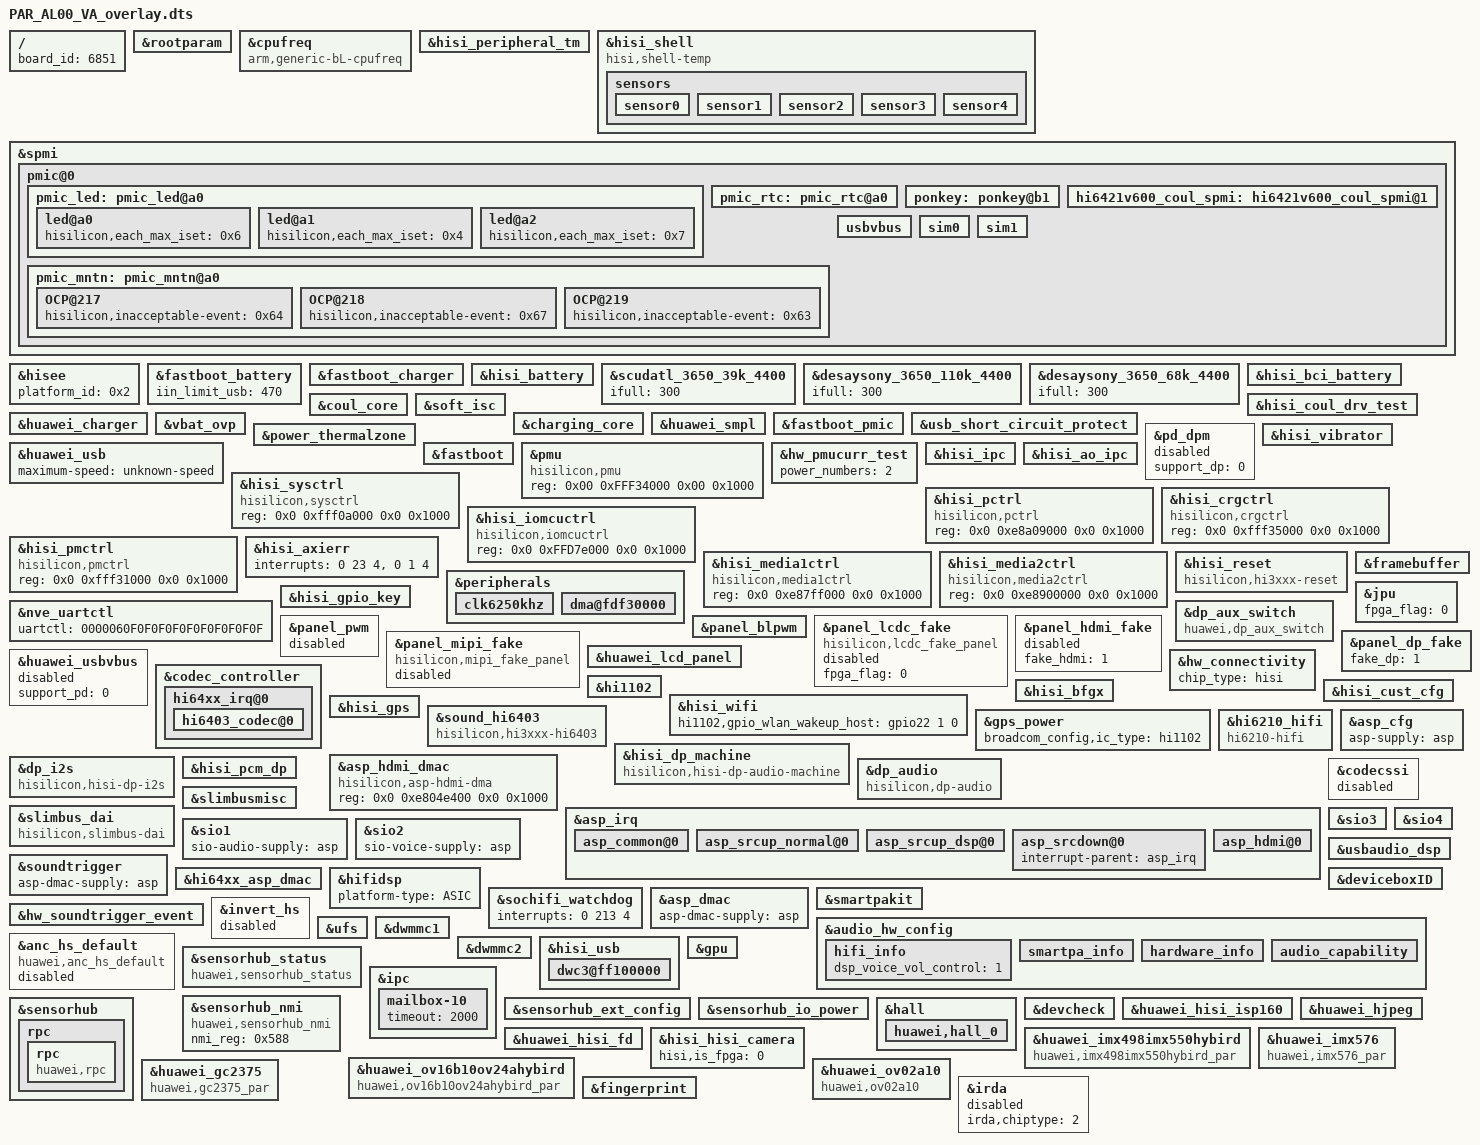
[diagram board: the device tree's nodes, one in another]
/**
 * Copyright (C) 2014 Hisilicon Ltd.
 *
 *  This program is free software; you can redistribute it and/or modify
 *  it under the terms of the GNU General Public License version 2 as
 *  publishhed by the Free Software Foundation.
 */

/dts-v1/;
/plugin/;

/include/ "PAR_AL00_VA_overlay_module_amba.dts"
/include/ "PAR_AL00_VA_overlay_module_sensorhub.dts"
/include/ "PAR_AL00_VA_overlay_module_ts_kit.dts"

/ {
	board_id = <6851>;
};

&rootparam {
        hisi,dtbo_idx = <66>;
    hisi,boardid = <6 8 5 1>;
    hisi,boardname = "PAR_AL00_VA";
};

	/* cpufreq  device */
	&cpufreq {
		compatible = "arm,generic-bL-cpufreq";
		status = "ok";
	};

	&hisi_peripheral_tm {
		hisi,peripheral_sensors = <8>;

		hisi,detect_system_h_tm_chanel = <7>;
		hisi,detect_system_h_tm_ntc = "austin_hkadc_soc_temp_table";
		hisi,detect_system_h_tm_state = "enable";
		hisi,detect_system_h_throttling = <53>;
		hisi,detect_system_h_shutdown = <55>;
		hisi,detect_system_h_below_vr_min = <53>;
		hisi,detect_system_h_over_skin = <12>;

		hisi,detect_flash_led_tm_chanel = <3>;
		hisi,detect_flash_led_tm_ntc = "austin_hkadc_soc_temp_table";
		hisi,detect_flash_led_tm_state = "disable";

		hisi,detect_charger_tm_chanel = <5>;
		hisi,detect_charger_tm_ntc = "austin_hkadc_soc_temp_table";
		hisi,detect_charger_tm_state = "enable";

		hisi,detect_pa_0_tm_chanel = <4>;
		hisi,detect_pa_0_tm_ntc = "austin_hkadc_pa_temp_table";
		hisi,detect_pa_0_tm_state = "enable";

		hisi,detect_pa_1_tm_chanel = <9>;
		hisi,detect_pa_1_tm_ntc = "austin_hkadc_pa_temp_table";
		hisi,detect_pa_1_tm_state = "disable";

		hisi,detect_dcxo0_tm_chanel = <15>;
		hisi,detect_dcxo0_tm_ntc = "austin_hkadc_adc_temp_table";
		hisi,detect_dcxo0_tm_state = "enable";

		hisi,detect_shell_tm_chanel = <7>;
		hisi,detect_shell_tm_ntc = "austin_hkadc_soc_temp_table";
		hisi,detect_shell_tm_state = "disable";

		hisi,detect_charger1_tm_chanel = <4>;
		hisi,detect_charger1_tm_ntc = "austin_hkadc_soc_temp_table";
		hisi,detect_charger1_tm_state = "disable";

		status = "ok";
	};

	&hisi_shell {
		compatible = "hisi,shell-temp";
		interval = <5000>;
		bias = <50000>;
		count = <6>;
		status = "ok";
		sensors {
			sensor0 {
				type = "system_h";
				coef = "-336","-311","1051","1148","761","-444";
			};
			sensor1 {
				type = "charger";
				coef = "2130","1143","-437","-800","478","2557";
			};
			sensor2 {
				type = "pa_0";
				coef = "16772","10594","5161","3140","7723","13923";
			};
			sensor3 {
				type = "dcxo0";
				coef = "-381","-1701","717","-1587","-2","-5589";
			};
			sensor4 {
				type = "Battery";
				coef = "12006","6346","3450","3824","4718","8474";
			};
		};
	};

	&spmi {
		pmic@0 {
			gpios = <&gpio28 0 0>;
			hisilicon,pmic_fpga_flag=<0>;
			pmic_led: pmic_led@a0 {
				status = "ok";
				led@a0 {
					hisilicon,each_max_iset = <0x6>;
				};
				led@a1 {
					hisilicon,each_max_iset = <0x4>;
				};
				led@a2 {
					hisilicon,each_max_iset = <0x7>;
				};
			};
			pmic_rtc: pmic_rtc@a0 {
				status = "ok";
			};
			ponkey:ponkey@b1{
				status = "ok";
			};
			pmic_mntn: pmic_mntn@a0 {
				status = "ok";
				OCP@217 {
					hisilicon,inacceptable-event = <0x64>;  //base E7
				};
				OCP@218 {
					hisilicon,inacceptable-event = <0x67>;  //base FF
				};
				OCP@219 {
					hisilicon,inacceptable-event = <0x63>;  //base 7F
				};
			};
			hi6421v600_coul_spmi: hi6421v600_coul_spmi@1 {
				status = "ok";
			};
			usbvbus {
				status = "ok";
			};
		};
	};

	&hisee {
		platform_id = <0x2>;
	};

	&fastboot_battery {
		iin_limit_usb = <470>;
		status = "ok";
	};
	&fastboot_charger {
		hw_charger_type = <4>;
		chip_i2c_num = <6>;
		status = "ok";
	};
	&hisi_battery {
		status = "ok";
		batt_name = <&scudatl_3650_39k_4400 &desaysony_3650_110k_4400 &desaysony_3650_68k_4400>;
	};

	&scudatl_3650_39k_4400 {
		ifull = <300>;
	};
	&desaysony_3650_110k_4400 {
		ifull = <300>;
	};
	&desaysony_3650_68k_4400 {
		ifull = <300>;
	};

	&hisi_bci_battery{
		battery_design_fcc = <3750>;
		battery_board_type = <2>; /*0:sft 1:udp 2:asic*/
		status = "ok";
	};
	&coul_core {
		adc_batt_id = <11>;
		adc_batt_temp = <10>;
		r_pcb = <0>;
		r_coul_mohm = <10>;
		startup_delta_soc = <10>;
		last_soc_enable = <1>;
		soc_at_term = <98>;
		iscd_enable = <1>;
		current_full_enable = <0>;
		ntc_compensation_is = <0>;
		ntc_temp_compensation_para =
			"0", "0";
		basp_policy = <
			4 100000 70  100 100 100 1 920001032 0
			3 70000  80  50  50  100 1 920001031 1
			2 40000  88  40  50  100 1 920001029 1
			1 20000  100 20  0   100 1 920001037 0
			0 0      0   0   0   100 0 0         0
		>;
		basp_ver = <2>;
		batt_backup_nv_flag = <1>;
		normal_cutoff_vol_mv = <3000>;
		low_vol_filter_cnt = <6>;
		status = "ok";
	};
	&soft_isc {
		/* 0 means invalid; 1 is successive judgement; others is illegal */
		fatal_isc_trigger_type = <1>;
		/*DMD normal-charge-limitation direct-charge-limitation Uevent OCV-update*/
		fatal_isc_actions = <1 1 1 1 1>;
		fatal_isc_trigger_condition = <50000 3 920001078 100000 2 920001077>;
	};
	&hisi_coul_drv_test{
		status = "ok";
	};
	&huawei_charger {
		pd_support = <0x0>;
		fcp_vindpm = <8100>;
		charge_done_sleep_enabled;
		leak_current_check = <1>;
		status = "ok";
	};
	&vbat_ovp{
		status = "ok";
	};
	&charging_core{
		status = "ok";
		iterm = <150>;
		iin_ac = <2000>;
		ichg_ac = <2100>;
		iin_usb = <470>;
		ichg_usb = <500>;
		ichg_fcp = <3600>;
		iin_fcp = <2000>;
		vdpm_buf_limit = <300>;
		iin_weaksource = <470>;
		vdpm_para =
			"-32767", "4080", "4460", "280",
			"4080", "32767", "4675", "280";
		inductance_para =
			"-32767", "15", "2000", "0",
			"15", "32767", "2000", "0";
	};
	&huawei_smpl{
		status = "ok";
	};
               &fastboot_pmic{
                             hisilicon,init-reg-num = <1>;
                             hisilicon,init-reg-addrs = <0x243>;
                             hisilicon,init-reg-vals  = <0x06>;
               };
	&usb_short_circuit_protect{
		open_mosfet_temp = <20>;
		close_mosfet_temp = <10>;
		interval_switch_temp = <15>;
		status = "ok";
	};

	&power_thermalzone {
		status = "ok";
	};

	&pd_dpm {
		status = "disabled";
		support_dp = <0>;
	};
	&huawei_usb {
		maximum-speed = "unknown-speed";
		status = "ok";
	};
	&hisi_vibrator {
		status = "ok";
		vibrator_vout_min_voltage = <3000000>;
                vibrator_vout_max_voltage = <3000000>;
	};
	&fastboot {
		i2c3-pin = <0>;
		gpio-keyup = <231>;
		gpio-keydown = <230>;
		uart-board-type = <1>;
		/*UDP_TYPE 0,PRODUCT 1,FPGA 2,EMU 3*/
		lpm3-board-type = <2>;
		jtagtosd-board-type = <1>;
		motor-vib_type = <0>;
		/*is_fpga = <0x55AA5AA5>;*/

		i2c-select = <1>;
		i2c-sel0-gpio = <44>;
		i2c-sel1-gpio = <45>;
		i2c-sel0-val = <0>;
		i2c-sel1-val = <0>;
	};

	&pmu{
		compatible = "hisilicon,pmu";
		reg = <0x00 0xFFF34000 0x00 0x1000>;
		status = "ok";
	};

	&hw_pmucurr_test{
		power_numbers = <2>;
		status = "ok";
	};

	&hisi_ipc {
		status = "ok";
	};
	&hisi_ao_ipc {
		status = "ok";
	};

        &hisi_sysctrl {
                compatible = "hisilicon,sysctrl";
                reg = <0x0 0xfff0a000 0x0 0x1000>;
                status = "ok";
        };

        &hisi_pctrl {
                compatible = "hisilicon,pctrl";
                reg = <0x0 0xe8a09000 0x0 0x1000>;
                status = "ok";
        };

        &hisi_crgctrl {
                compatible = "hisilicon,crgctrl";
                reg = <0x0 0xfff35000 0x0 0x1000>;
                status = "ok";
        };

        &hisi_iomcuctrl {
                compatible = "hisilicon,iomcuctrl";
                reg = <0x0 0xFFD7e000 0x0 0x1000>;
                status = "ok";
		};
        &hisi_pmctrl {
                compatible = "hisilicon,pmctrl";
                reg = <0x0 0xfff31000 0x0 0x1000>;
                status = "ok";
        };
        &hisi_media1ctrl {
                compatible = "hisilicon,media1ctrl";
                reg = <0x0 0xe87ff000 0x0 0x1000>;
                status = "ok";
        };
        &hisi_media2ctrl {
                compatible = "hisilicon,media2ctrl";
                reg = <0x0 0xe8900000 0x0 0x1000>;
                status = "ok";
        };

	&hisi_axierr {
	        interrupts = <0 23 4>, <0 1 4>;
	        status = "ok";
        };

    &hisi_reset {
            compatible = "hisilicon,hi3xxx-reset";
            status = "ok";
        };

	&peripherals {

		clk6250khz {
			#clock-cells = <0>;
			clock-frequency = <6297600>;
			clock-output-names = "clk6250khz";
		};
/*
		clk4800khz {
			compatible = "fixed-clock";
			#clock-cells = <0>;
			clock-frequency = <32768>;
			clock-output-names = "clk4800khz";
		};
*/

		dma@fdf30000 {
			status = "ok";
		};

	};
	&nve_uartctl {
		uartctl = "0000060F0F0F0F0F0F0F0F0F0F";
	};

	&hisi_gpio_key {
		pinctrl-names = "default", "idle";
		pinctrl-0 = <&gpio231_cfg_func &gpio230_cfg_func>;
		pinctrl-1 = <&gpio231_cfg_idle &gpio230_cfg_idle>;
		gpio-keyup,gpio-irq = <&gpio28 7 0>;
		gpio-keydown,gpio-irq = <&gpio28 6 0>;
		status = "ok";
	};

	&dp_aux_switch {
	        compatible = "huawei,dp_aux_switch";
	        pinctrl-names = "default", "idle";
	        pinctrl-0 = <&gpio009_pmx_func &gpio010_pmx_func &gpio009_cfg_func &gpio010_cfg_func>;
	        pinctrl-1 = <&gpio009_pmx_idle &gpio010_pmx_idle &gpio009_cfg_idle &gpio010_cfg_idle>;
	        cs-gpios = <&gpio1 1 0>, <&gpio1 2 0>;
	        status = "ok";
	};

	/* display start */
	&framebuffer{
		fpga_flag = <0>;
		//FB_ACCEL_KIRIN970_ES  0x20;FB_ACCEL_KIRIN970  0x40;
		dss_version_tag = <0x40>;
	};

	/*jpeg decode */
	&jpu {
		fpga_flag = <0>;
	};

	&panel_pwm {
		#address-cells = <2>;
		#size-cells = <2>;
		clocks = <&clk_gate_pwm>;
		clock-names = "clk_pwm";
		//pinctrl-names = "default","idle";
		//pinctrl-0 = <&gpio182_pmx_func &gpio182_cfg_func>;
		//pinctrl-1 = <&gpio182_pmx_idle &gpio182_cfg_idle>;
		fpga_flag = <0>;
		status = "disabled";
	};

	&panel_blpwm {
		#address-cells = <2>;
		#size-cells = <2>;
		clocks = <&clk_gate_blpwm>;
		clock-names = "clk_blpwm";
		pinctrl-names = "default","idle";
		pinctrl-0 = <&gpio184_pmx_func &gpio185_pmx_func &gpio184_cfg_func &gpio185_cfg_func>;
		pinctrl-1 = <&gpio184_pmx_idle &gpio185_pmx_idle &gpio184_cfg_idle &gpio185_cfg_idle>;
		fpga_flag = <0>;
		status = "ok";
	};

	&panel_lcdc_fake {
		#address-cells = <2>;
		#size-cells = <2>;
		compatible = "hisilicon,lcdc_fake_panel";
		fpga_flag = <0>;
		status = "disabled";
	};

	&panel_mipi_fake {
		#address-cells = <2>;
		#size-cells = <2>;
		compatible = "hisilicon,mipi_fake_panel";
		gpios = <&gpio4 2 0>, <&gpio6 3 0>, <&gpio1 4 0>; /* vsn, bl_enable, vsp*/
		gpio_nums = <34 51 12>;
		fpga_flag = <0>;
		lcd-bl-ic-name = "LM36923YFFR";
		bl_enable_flag = <0>;
		status = "disabled";
	};

	&huawei_lcd_panel {
		lcd_ldo_name = "LDO4";
		lcd_ldo_channel = <2>;
		lcd_ldo_threshold = <200>;
		lcd-bl-ic-name = "blpwm_blic";
	};


	&panel_hdmi_fake {
		fake_hdmi = <1>;
		status = "disable";
	};
	&panel_dp_fake {
		fake_dp = <1>;
		status = "ok";
	};
	&huawei_usbvbus {
		support_pd = <0>;
		status = "disabled";
	};

	/* display end */



	/* audio device beg */
	&codec_controller {
		gpios = <&gpio18 4 0>; /* GPIO_148 */
		gpio_reset = <31>; /* GPIO_031*/
		gpio_codec_ssi = <203>;
		gpio_codec_ssi_func = <1>;
		pm_runtime_support;
		status = "ok";

		hi64xx_irq@0 {
			status = "ok";

			hi6403_codec@0{
				hisilicon,mic_num = <2>;
				hisilicon,hs_4_pole_min_voltage = <900>;
				use_stereo_smartpa = <0>;
				hisilicon,hs_det_trigger = <1>;
				hisilicon,hs_extern_cable_min_voltage = <2651>;
				hisilicon,hs_extern_cable_max_voltage = <2700>;
				hs_detect_extern_cable = <1>;
				hisilicon,wakeup_hisi_algo_support = <1>;
				status = "ok";
			};
		};
	};

	&hw_connectivity {
		chip_type = "hisi";
	};

	/*power*/
	&hi1102 {
	};

	/*wifi*/
	&hisi_wifi {
		hi1102,gpio_wlan_wakeup_host =  <&gpio22 1 0>;
	};

	/*bfgx*/
	&hisi_bfgx {
		hi1102,gpio_bfgn_wakeup_host = <&gpio27 2 0>;
		hi1102,uart_port = "/dev/ttyAMA4";
	hi1102,uart_pclk_normal;
	/**ir begin*/
		hi1102,irled_power_type=<0x00>;
		have_ir;
	/**ir end*/
	};

	/*hisi connectivity customize*/
	&hisi_cust_cfg {
	};

	/*hisi gps*/
	&hisi_gps {
		clocks = <&clk_gate_gps_ref>, <&clk_mux_gps_ref>, <&clk_gate_mdm2gps0>, <&clk_gate_mdm2gps1>, <&clk_gate_mdm2gps2>;
		clock-names = "ref_clk", "mux_clk", "mdm_clk0", "mdm_clk1", "mdm_clk2";
		/*hisi gps iomux config*/
		pinctrl-names = "default", "idle";
		pinctrl-0 = <&gpio005_pmx_func &gpio005_cfg_func>;
		pinctrl-1 = <&gpio005_pmx_idle &gpio005_cfg_idle>;
	};

	&gps_power{
		broadcom_config,ic_type="hi1102";
	};
	&sound_hi6403 {
		compatible = "hisilicon,hi3xxx-hi6403";
		status = "ok";
	};

	&hi6210_hifi {
		compatible = "hi6210-hifi";
		status = "ok";
	};

	&hisi_dp_machine {
		compatible = "hisilicon,hisi-dp-audio-machine";
		status = "ok";
	};

	&asp_hdmi_dmac {
		compatible = "hisilicon,asp-hdmi-dma";
		reg = <0x0 0xe804e400 0x0 0x1000>;
		status = "ok";
	};

	&asp_cfg {
		asp-supply = <&asp>;
		status = "ok";
	};

	&dp_i2s {
		compatible = "hisilicon,hisi-dp-i2s";
		status = "ok";
        };

	&dp_audio {
		compatible = "hisilicon,dp-audio";
		status = "ok";
        };

	&hisi_pcm_dp {
		interrupts = <0x0 0x96 0x4>;
		interrupt-names = "asp_hdmi_dma";
		dp-pcm-supply = <&asp>;
		status = "ok";
	};

	&asp_irq{

		asp_common@0 {
		};

		asp_srcup_normal@0 {
			asp-srcup-normal-supply = <&asp>;
			interrupt-parent = <&asp_irq>;
			interrupts = <0x1 0x0>;
			interrupt-names = "asp_srcup_normal";
		};

		asp_srcup_dsp@0 {
		};

		asp_srcdown@0 {
			interrupt-parent = <&asp_irq>;
		};

		asp_hdmi@0 {
			interrupt-parent = <&asp_irq>;
			interrupts = <0x0 0x0>;
			interrupt-names = "asp_irq_hdmi";
		};
	};
	&codecssi {
		/* ssi pinctrl */
		pinctrl-names = "default", "idle";
		pinctrl-0 = <&gpio203_cfg_func &gpio203_pmx_func>;
		pinctrl-1 = <&gpio203_cfg_idle &gpio203_pmx_idle>;
		status = "disabled";
	};
	&slimbusmisc {
		interrupts = <0x0 0x96 0x4>;
		interrupt-names = "asp_irq_slimbus";
		slimbus-reg-supply = <&asp>;
		pinctrl-names = "default", "idle";
		pinctrl-0 = <&gpio192_pmx_func
				&gpio193_pmx_func
				&gpio192_cfg_func
				&gpio193_cfg_func>;
		pinctrl-1 = <&gpio192_pmx_idle
				&gpio193_pmx_idle
				&gpio192_cfg_idle
				&gpio193_cfg_idle>;
		slimbus-ssi-sel = "slimbus";
		asp_power_state_offset = <0x06c>;
		slimbusclk_offset = <0x038>;
		slimbusdata_offset = <0x03c>;
		slimbusclk_cfg_offset = <0x864>;
		slimbusdata_cfg_offset = <0x868>;
		platform-type   = "ASIC";
		codec-type = "slimbus-6403cs";
		clk_asp_subsys = <415000>;
		slimbus_dynamic_freq= "true";
		pm_runtime_support;
		status = "ok";
	};
	&slimbus_dai {
		compatible = "hisilicon,slimbus-dai";
		status = "ok";
	};

	&sio1 {
		sio-audio-supply = <&asp>;
		/* wbd
		pinctrl-names = "default", "idle";
		pinctrl-0 = <&gpio183_pmx_func
				    &gpio184_pmx_func
				    &gpio185_pmx_func
				    &gpio186_pmx_func
				    &gpio183_cfg_func
				    &gpio184_cfg_func
				    &gpio185_cfg_func
				     &gpio186_cfg_func>;
		pinctrl-1 = <&gpio183_pmx_idle
				    &gpio184_pmx_idle
				    &gpio185_pmx_idle
				    &gpio186_pmx_idle
				    &gpio183_cfg_idle
				    &gpio184_cfg_idle
				    &gpio185_cfg_idle
				    &gpio186_cfg_idle>;
		*/
		status = "ok";
	};

	&sio2 {
		sio-voice-supply = <&asp>;
		/* wbd
		pinctrl-names = "default", "idle";
		pinctrl-0 = <&gpio043_pmx_func
				     &gpio044_pmx_func
				     &gpio045_pmx_func
				     &gpio046_pmx_func
				     &gpio043_cfg_func
				     &gpio044_cfg_func
				     &gpio045_cfg_func
				     &gpio046_cfg_func>;
			pinctrl-1 = <&gpio043_pmx_idle
				     &gpio044_pmx_idle
				     &gpio045_pmx_idle
				     &gpio046_pmx_idle
				     &gpio043_cfg_idle
				     &gpio044_cfg_idle
				     &gpio045_cfg_idle
				     &gpio046_cfg_idle>;
		*/
		status = "ok";
	};

	&sio3 {
	};

	&sio4 {
	};

	&soundtrigger {
		asp-dmac-supply = <&asp>;
		status = "ok";
	};

	&hi64xx_asp_dmac {
		asp-dmac-supply = <&asp>;
		interrupts = <0 216 4>;
		interrupt-names = "asp_dma_irq";
		status = "ok";
	};

	&hifidsp {
			platform-type = "ASIC";
	};

	&sochifi_watchdog {
		interrupts = <0 213 4>;
		status = "ok";
	};

	&asp_dmac {
		asp-dmac-supply = <&asp>;
		status = "ok";
	};

	&usbaudio_dsp {
	};

	&deviceboxID {
		check_mode = "gpio";
		box_num = <1>;
		enable_boxID = <1 0 0 0>;
		gpio_num = <1 0 0 0>;
		gpio_speakerID = <&gpio17 1 0>;
		speaker_map = <3 1>;/*3 means GD, 1 means AAC*/
		pinctrl-names = "default", "idle";
		pinctrl-0 = <&gpio137_pmx_func &gpio137_cfg_func>;
		pinctrl-1 = <&gpio137_pmx_idle &gpio137_cfg_idle>;
		deviceboxID_limit = <500>;
		status = "ok";
	};

	&smartpakit {
		/* 0 hisi, 1 qcom */
		soc_platform = <0>;
		/* algo running on: 0 codec_dsp, 1 soc_dsp, 2 smartpa_dsp, 3 simple pa(not smpartpa) */
		algo_in = <0>;
		/* algo_in params need match out_device for smartpa.
		 * Now, up to only support four pa, so out_device = <0 0 0 0>;
		 * 1. This array is arranged in the following order:
		 *    <0 1 2 3>
		 *    <pril prir secl secr>
		 * 2. This array element value is 0 or 1:
		 *    smartpa: 0 speaker, 1 receiver
		 *    simple pa: out_device not applicable, only set 0 to indicate pa_num
		 * 3. The length of this array is variable, for example:
		 *    single pa: out_device = <0>;
		 *    two pa: out_device = <0 0>;
		 *    four pa: out_device = <1 1 0 0>; */
		out_device = <0>;
		dsp_img_name = "hifi_6403_tas_devkit.img";
		status = "ok";
	};

	&audio_hw_config {
		product_name = "PAR";
		multi_mic_enable = "false";
		vqm_enable = "true";
		spk_pa_name = "smartpakit";
		cust_name = "audio_custom";
		soc_name = "hi363x";
		codec_name = "hi6403";
		codec_dsp_algo = "mad";
		modem_sio_master = "false";
		asr_enable = "true";
		analog_earpiece_enable = "false";
		status = "ok";
		audio_sar_support = "true";
		karaoke_mic_conf_support = "true";/*use specific mic path to enhance karaoke UE*/

		hifi_info {
			dsp_voice_vol_control = "1";/* 1 :need socdsp control volume; 0:platform codec */
		};

		smartpa_info {
			pa_num = "1";
			algo_in = "0"; /*algo running on: 0 codec_dsp | 1 soc_dsp | 2 smartpa_dsp */
			pa_type = "0001";/*0 as receiver pa 1 as spk pa eg:0011 means dual smartpa and only as spk, 0001 means dual smartpa and as spk+rcv*/
			status = "ok";
		};

		hardware_info {
			mic_num = "2";
			mic_type = "0003";/*0001 deputy mic   0002 main mic   0004 deputy mic2   0008 main mic2*/
			status = "ok";
		};

		audio_capability {
			bwe_ui_support = "false";
			bwe_support = "true";
			swb_support = "true";
			wnr_support = "false";
			nv_evs_support = "true";
			lvm_support = "false";
			dhf_support = "false";
			voice_anc_support = "false";
			dual_smartpa_support = "false";
			stereo_handfree_support = "false";
			spk_rcv_stereo_support = "false";
			earphone_multi_eq_support = "false";
			vdr_ui_support = "false";
			asr_vibrate_support = "true";
			mmi_capture_enable = "true";
			irda_support = "false";
			visualizer_support = "true";
			visualizer_frame = "Medium";
			/*
				sound trigger feature.
				false: this product doesn't support soundtrigger feature.
				2.0: this product supports the twice wakeup feature.
			*/
			soundtrigger_version = "2.0";
			/*
				max stream volume to replace Android default volume.
			*/
			max_stream_volume = "15";
			/*
				usb compatibility report feature.
				true: this product needs usb compatibility report.
				false: this product doesn't need usb compatibility report.
			*/
			usb_compatibility_report = "true";
			/*
				use hisilicon wakeup engine.
				true: use hisilicon wakeup engine.
				false: DO NOT use hisilicon wakeup engine.
			*/
			wakeup_hisiengine = "true";
		};
	};

	&hw_soundtrigger_event{
		status = "ok";
	};

	&invert_hs {
		gpios = <&gpio26 0 0>;
		gpio_type = <0>;
		pinctrl-names = "default", "idle";
		pinctrl-0 = <&gpio208_pmx_func &gpio208_cfg_func>;
		pinctrl-1 = <&gpio208_pmx_idle &gpio208_cfg_idle>;
		status = "disabled";
	};

	&anc_hs_default {
		compatible = "huawei,anc_hs_default";
		status = "disabled";
	};

	/* audio device end */

	/*bootdevice: bootdevice {
		boot-from-emmc;
	};*/

	/* UFS */
	&ufs {
		ufs-kirin-use-rate-B;
		ufs-kirin-broken-fastauto;
		/*ufs-kirin-use-one-line;*/
		ufs-kirin-use-HS-GEAR3;
		/*ufs-kirin-use-HS-GEAR2;*/
		/*ufs-kirin-use-HS-GEAR1;*/
		ufs-kirin-unipro-termination;
		/*ufs-kirin-unipro-scrambing;*/
		/*ufs-kirin-disable-pm-runtime;*/
		/*ufs-kirin-use-auto-H8*/
		ufs-kirin-broken-clk-gate-bypass;
		status = "ok";
	};

	/* eMMC 4.5 */

	/* SD */
	&dwmmc1 {
		vmmc-supply = <&ldo16>;
		vqmmc-supply = <&ldo9>;
		cd-vol = <1>;
		cd-gpio = <&gpio25 5 0>;
		shared-irq = <1>;
		cs_sd_timing_config;
		status = "ok";
	};

	/* wifi */
	&dwmmc2 {
	};

	&hisi_usb {
		usb_ldo_disable = <1>;
		usb_aclk_freq = <238000000>;
		usb_support_dp = <0>;

		eye_diagram_param = <0x37CE7E7>;
		eye_diagram_host_param = <0x33DE7E7>;
		usb_support_check_voltage = <0>;
		dwc3@ff100000 {
			quirk_dplus_gpio = <0>;
			maximum-speed = "high-speed";
		};
	};

	&gpu {
		status = "ok";
	};

	&sensorhub_status{
		compatible = "huawei,sensorhub_status";
		status= "ok";
	};

	&ipc {	/* add for fpga because iom7 start too slow锛?300ms锛?*/
		mailbox-10 {
			timeout = <2000>;
		};
	};

	&sensorhub_nmi{
		compatible = "huawei,sensorhub_nmi";
		nmi_reg=<0x588>;
	};

	&sensorhub_ext_config {
		akm_need_current = "no";
		invensense_exist = "no";
		isensor_version = "no";
		sensor_1v8_from_pmic = "no";
		adapt_sensor_list_id = <2 6 7 8 11 12 13 14 15 17 18 21 29>;
		adapt_file_id = <8 9 14 15>;
	};

	&sensorhub_io_power{
		sensor-io-supply = <&ldo24>;
		need-reset = <1>;
		set-3v = <1>;
		status="ok";
	};

	&sensorhub{
		rpc{
            		rpc{
			compatible = "huawei,rpc";
			file_id = <0x18>;
			sensor_list_info_id = <24>;
			sensor_type = "rpc";
			sensorlist_name = "rpc";
			mask = <0xFFFF 0x200 0x200 0xFFFF 0xFFFF 0xFFFF 0xFFFF 0xFFFF
				0xFFFF 0xFFFF 0xFFFF 0xFFFF 0xFFFF 0xFFFF 0xFFFF 0xFFFF
				0xFFFF 0xFFFF 0xFFFF 0xFFFF 0xFFFF 0xFFFF 0xFFFF 0xFFFF
				0xFFFF 0xFFFF 0xFFFF 0xFFFF 0xFFFF 0xFFFF 0xFFFF 0xFFFF>;
			table = <0xFFFF 0x200 0x0 0xFFFF 0xFFFF 0xFFFF 0xFFFF 0xFFFF
				 0xFFFF 0xFFFF 0xFFFF 0xFFFF 0xFFFF 0xFFFF 0xFFFF 0xFFFF
				 0xFFFF 0xFFFF 0xFFFF 0xFFFF 0xFFFF 0xFFFF 0xFFFF 0xFFFF
				 0xFFFF 0xFFFF 0xFFFF 0xFFFF 0xFFFF 0xFFFF 0xFFFF 0xFFFF>;
			default_value = <0x1D>;
			status = "ok";
            };
        };

	};

	&hall {
		huawei,hall_0{
			huawei,single-n-pole = <&gpio27 1 0>;
			huawei,type = <0x01>;
			huawei,default-state = "on";
		};
	};

	&devcheck {
		touch_panel = <2>;
		compass = <3>;
		g_sensor = <3>;
		gyroscope = <3>;
		nfc = <0>;
		dc_dc = <3>;
		tps = <0>;
		l_sensor = <2>;
		charge = <3>;
		antenna_ctl = <0>;
		airpress = <0>;
		laser = <0>;
		status = "ok";
	};

	&huawei_hisi_isp160 {
		hisi,is_fpga = <0>;
                pinctrl-names = "default", "idle";
                pinctrl-0 = <
                 &gpio017_pmx_func
                 &gpio018_pmx_func
                 &gpio019_pmx_func
                 &gpio020_pmx_func
                 &gpio021_pmx_func
                 &gpio022_pmx_func
                 &gpio023_pmx_func
                 &gpio024_pmx_func
                 &gpio025_pmx_func
                 &gpio008_pmx_func
                 &gpio004_pmx_func
                 &gpio136_pmx_func
                 &gpio013_pmx_func
                 &gpio032_pmx_func

                 &gpio017_cfg_func
                 &gpio018_cfg_func
                 &gpio019_cfg_func
                 &gpio020_cfg_func
                 &gpio021_cfg_func
                 &gpio022_cfg_func
                 &gpio023_cfg_func
                 &gpio024_cfg_func
                 &gpio025_cfg_func
                 &gpio008_cfg_func
                 &gpio004_cfg_func
                 &gpio136_cfg_func
                 &gpio013_cfg_func
                 &gpio032_cfg_func
                 >;
                pinctrl-1 = <
                 &gpio017_pmx_idle
                 &gpio018_pmx_idle
                 &gpio019_pmx_idle
                 &gpio020_pmx_idle
                 &gpio021_pmx_idle
                 &gpio022_pmx_idle
                 &gpio023_pmx_idle
                 &gpio024_pmx_idle
                 &gpio025_pmx_idle
                 &gpio008_pmx_idle
                 &gpio004_pmx_idle
                 &gpio136_pmx_idle
                 &gpio013_pmx_idle
                 &gpio032_pmx_idle

                 &gpio017_cfg_idle
                 &gpio018_cfg_idle
                 &gpio019_cfg_idle
                 &gpio020_cfg_idle
                 &gpio021_cfg_idle
                 &gpio022_cfg_idle
                 &gpio023_cfg_idle
                 &gpio024_cfg_idle
                 &gpio025_cfg_idle
                 &gpio008_cfg_idle
                 &gpio004_cfg_idle
                 &gpio136_cfg_idle
                 &gpio013_cfg_idle
                 &gpio032_cfg_idle
                 >;
                status = "ok";
	};

	&huawei_hjpeg {
		huawei,hjpeg-base = <0xE8300000 0x1000>;
		huawei,smmu-base = <0xE8320000 0x20000>;
		huawei,cvdr-base = <0xE8302000 0x1000>;
		huawei,subctrl-base = <0xE8304000 0x4>;
		huawei,chip_type = <1>;
		huawei,smmu_bypass = <0>;
		huawei,smmu_type = <1>;
		huawei,power_control = <0>;
		huawei,cvdr = <0 0 0>;
		huawei,stream_id = <0 4 5>;
		clocks = <&clk_gate_jpg_func>;
		clock-names = "clk_jpg_func";
		clock-value = <554000000>;
		clock-low-frequency = <277000000>;
		power-off-frequency = <238000000>;
		reg = <0 0xE8300000 0 0x1000>;
		interrupts = <0 299 4>;
		hjpeg-srt-supply = <&ispsubsys>;
		hjpeg-media-supply = <&media_subsys>;
		status = "ok";
	};

    &huawei_hisi_fd {
        huawei,top-base = <0xE8304000 0x1000>;
        hisi-fd-supply = <&ispsubsys>;
        hisi-media-supply = <&media_subsys>;
        clocks = <&clk_gate_fd_func>;
        clock-names = "clk_fd_func";
        clock-value = <300000000>;
        clock-low-frequency = <277000000>;
        interrupts = <0 307 4>;
        huawei,smmu-flag = <0>;
        fd-pwr-seq = "fd_regulator","fd_clk";
        smmu_offset_list = <0x10 0x1c 0x20 0x204 0x20c 0x220 0x224>;
        mstr_offset_list = <0x28 0x34 0x100 0x260 0x3c0>;
        fd_offset_list = <0x418 0x40c 0x410 0x414 0x464 0xFD 0x7A 0x9F 0x58 0x31c 0x470>;

        status = "ok";
    };

	&hisi_hisi_camera {
		hisi,is_fpga = <0>;
	};

	&huawei_imx498imx550hybird {
		compatible = "huawei,imx498imx550hybird_par";
		huawei,sensor_name = "IMX498IMX550";
		huawei,sensor_index = <0>;
		huawei,is_fpga = <0>;
		huawei,pd_valid = <1>;
		huawei,reset_valid = <1>;
		huawei,vcmpd_valid = <0>;
		huawei,csi_index = <0 2>;
		huawei,i2c_index = <0 2>;
		huawei,flash_pos_type = <1>;//MIX
		clocks = <&clk_gate_isp_snclk0 &clk_gate_isp_snclk2>;
		clock-names = "clk_isp_snclk0", "clk_isp_snclk2";
		huawei,mclk = <24000000>;
		avdd-supply = <&ldo33>;
		avdd2-supply = <&ldo13>;
		dvdd-supply = <&ldo19>;
		dvdd2-supply = <&ldo20>;
		vcm-supply = <&ldo25>;
		vcm2-supply = <&ldo34>;
		iovdd-supply = <&ldo21>;
		huawei,ldo-names ="avdd", "avdd2", "dvdd", "dvdd2", "vcm", "vcm2", "iovdd";
		gpios = <&gpio1 5 0 &gpio17 0 0  &gpio1 0 0 &gpio4 0 0 &gpio28 3 0 &gpio1 6 0>;
		huawei,gpio-ctrl-types = "reset", "reset2", "mipisw", "suspend", "suspend2", "pwdn";
		module_type = <0>;/*bit0=enable ,other bits=type*/
		status = "ok";
	};

	&huawei_ov16b10ov24ahybird{
		compatible = "huawei,ov16b10ov24ahybird_par";
		huawei,sensor_name = "OV16B10OV24A";
		huawei,sensor_index = <0>;
		huawei,is_fpga = <0>;
		huawei,pd_valid = <1>;
		huawei,reset_valid = <1>;
		huawei,vcmpd_valid = <0>;
		huawei,csi_index = <0 2>;
		huawei,i2c_index = <0 2>;
		huawei,flash_pos_type = <1>;//MIX
		clocks = <&clk_gate_isp_snclk0 &clk_gate_isp_snclk2>;
		clock-names = "clk_isp_snclk0", "clk_isp_snclk2";
		huawei,mclk = <24000000>;
		avdd-supply = <&ldo33>;
		avdd2-supply = <&ldo13>;
		dvdd-supply = <&ldo19>;
		dvdd2-supply = <&ldo20>;
		vcm-supply = <&ldo25>;
		vcm2-supply = <&ldo34>;
		iovdd-supply = <&ldo21>;
		huawei,ldo-names ="avdd", "avdd2", "dvdd", "dvdd2", "vcm", "vcm2", "iovdd";
		gpios = <&gpio1 5 0 &gpio17 0 0  &gpio1 0 0 &gpio4 0 0 &gpio28 3 0 &gpio1 6 0>;
		huawei,gpio-ctrl-types = "reset", "reset2", "mipisw", "suspend", "suspend2", "pwdn";
		module_type = <0>;/*bit0=enable ,other bits=type*/
		status = "ok";
	};

	&huawei_imx576 {
		compatible = "huawei,imx576_par";
		huawei,sensor_name = "IMX576";
		huawei,is_fpga = <0>;
		huawei,pd_valid = <1>;
		huawei,sensor_index = <1>;
		huawei,csi_index = <1>;
		huawei,i2c_index = <1>;
		huawei,reset_valid = <1>;
		huawei,flash_pos_type = <1>;//MIX
		clock-names = "clk_isp_snclk1";
		clocks = <&clk_gate_isp_snclk1>;
		huawei,mclk = <24000000>;
		huawei,vcmpd_valid = <0>;
		avdd-supply = <&ldo13>;
		dvdd-supply = <&ldo32>;
		iovdd-supply = <&ldo21>;
		vcm-supply = <&ldo25>;
		huawei,ldo-names = "avdd", "dvdd", "iovdd", "vcm";
		gpios = <&gpio4 0 0 &gpio1 0 0 &gpio1 5 0 &gpio17 0 0 &gpio1 6 0>;
		huawei,gpio-ctrl-types = "reset", "mipisw", "suspend", "suspend2", "pwdn";
		status = "ok";
	};

	&huawei_ov02a10 {
		compatible = "huawei,ov02a10";
		huawei,sensor_name = "OV02A10";
		huawei,is_fpga = <0>;
		huawei,pd_valid = <1>;
		huawei,sensor_index = <3>;
		huawei,csi_index = <0>;
		huawei,i2c_index = <0>;
		huawei,reset_valid = <1>;
		huawei,flash_pos_type = <1>;//MIX
		clock-names = "clk_isp_snclk0";
		clocks = <&clk_gate_isp_snclk0>;
		huawei,mclk = <24000000>;
		huawei,vcmpd_valid = <0>;
		avdd-supply = <&ldo33>;
		iovdd-supply = <&ldo21>;//iovdd & dvdd
		vcm-supply = <&ldo25>;
		huawei,ldo-names = "avdd", "iovdd", "vcm";
		gpios = <&gpio28 3 0 &gpio1 0 0 &gpio1 6 0 &gpio1 5 0 &gpio17 0 0>;
		huawei,gpio-ctrl-types = "reset", "mipisw", "pwdn", "suspend", "suspend2";
		status = "ok";
	};

	&huawei_gc2375 {
		compatible = "huawei,gc2375_par";
		huawei,sensor_name = "GC2375";
		huawei,is_fpga = <0>;
		huawei,pd_valid = <1>;
		huawei,sensor_index = <3>;
		huawei,csi_index = <0>;
		huawei,i2c_index = <0>;
		huawei,reset_valid = <1>;
		huawei,flash_pos_type = <1>;//MIX
		clock-names = "clk_isp_snclk0";
		clocks = <&clk_gate_isp_snclk0>;
		huawei,mclk = <24000000>;
		huawei,vcmpd_valid = <0>;
		avdd-supply = <&ldo33>;
		iovdd-supply = <&ldo21>;//iovdd & dvdd
		vcm-supply = <&ldo25>;
		huawei,ldo-names = "avdd", "iovdd", "vcm";
		gpios = <&gpio28 3 0 &gpio1 0 0 &gpio1 6 0 &gpio1 5 0 &gpio17 0 0>;
		huawei,gpio-ctrl-types = "reset", "mipisw", "pwdn", "suspend", "suspend2";
		status = "ok";
	};

	&fingerprint {
		spi-max-frequency = <5000000>;
		fingerprint,product = "paris";

		fingerprint,navigation_adjust1 = <0>;
		fingerprint,navigation_adjust2 = <0>;

		fingerprint,fpc2050 = <1>;
		fingerprint,reset_gpio = <211>;
		fingerprint,irq_gpio = <210>;
		fingerprint,cs_gpio = <216>;
		fingerprint,spi_num = <2>;
		fingerprint,force_storage_type = <1>;
	};

	&irda {
		irda,chiptype = <2>;		/*hisi1102*/
		status="disabled";
	};


    
    &spmi{
        pmic@0 {
            sim0 {
                gpios = <&gpio25 5 0>;
                sim_id = <0>;
                status = "ok";
                func_sel_state = "not_use_multi_func";
                det_normal_direction = "closed";
                allocate_gpio = <0>;
                shared_det_irq = <1>;
                send_msg_to_cp = <1>;
                card_tray_style = <1>;
                hpd_interrupt_to_close_ldo = <0x0A>;
                hpd_debounce_wait_time = <0x00>;
                det_debounce_wait_time = <300>;
                interrupt-parent = <&pmic>;
                interrupts = <11 0>;
                interrupt-names = "hpd0_falling";
                pmu_status1_address = <0x007>;
                pmu_ldo11_onoff_eco_address = <0x01D>;
                pmu_ldo11_vset_address = <0x058>;
                pmu_ldo12_onoff_eco_address = <0x01E>;
                pmu_ldo12_vset_address = <0x059>;
                pmu_sim_ctrl_address = <0x169>;
                pmu_sim_deb_ctrl_address = <0x16B>;
                pmu_irq_mask_address = <0x203>;
                pmu_irq_address = <0x213>;
                pmu_ldo11_onoff_value = <0x03>;
                pmu_ldo11_vset_value = <0x01>;
                pmu_ldo12_onoff_value = <0x03>;
                pmu_ldo12_vset_value = <0x01>;
                send_card_out_msg_when_init = <0>;
            };

            sim1 {
                gpios = <&gpio25 5 0>;
                sim_id = <1>;
                status = "ok";
                func_sel_state = "not_use_multi_func";
                det_normal_direction = "closed";
                allocate_gpio = <0>;
                shared_det_irq = <1>;
                send_msg_to_cp = <1>;
                card_tray_style = <1>;
                hpd_interrupt_to_close_ldo = <0x0A>;
                hpd_debounce_wait_time = <0x00>;
                det_debounce_wait_time = <300>;
                interrupt-parent = <&pmic>;
                interrupts = <13 0>;
                interrupt-names = "hpd1_falling";
                pmu_status1_address = <0x007>;
                pmu_ldo11_onoff_eco_address = <0x01D>;
                pmu_ldo11_vset_address = <0x058>;
                pmu_ldo12_onoff_eco_address = <0x01E>;
                pmu_ldo12_vset_address = <0x059>;
                pmu_sim_ctrl_address = <0x169>;
                pmu_sim_deb_ctrl_address = <0x16B>;
                pmu_irq_mask_address = <0x203>;
                pmu_irq_address = <0x213>;
                pmu_ldo11_onoff_value = <0x03>;
                pmu_ldo11_vset_value = <0x01>;
                pmu_ldo12_onoff_value = <0x03>;
                pmu_ldo12_vset_value = <0x01>;
                send_card_out_msg_when_init = <0>;
            };
        };
    };
    

